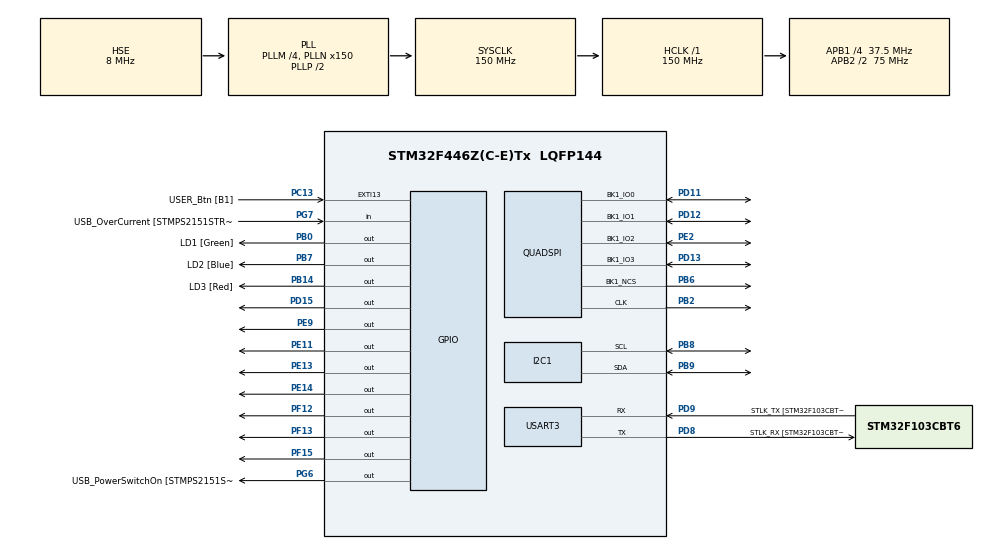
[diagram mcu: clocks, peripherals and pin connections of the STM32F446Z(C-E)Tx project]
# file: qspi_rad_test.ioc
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Mcu.Family=STM32F4
Mcu.Name=STM32F446Z(C-E)Tx
Mcu.Package=LQFP144
NVIC.PriorityGroup=NVIC_PRIORITYGROUP_4
PA10.GPIO_Label=USB_ID
PA10.Signal=USB_OTG_FS_ID
PA11.GPIO_Label=USB_DM
PA11.Signal=USB_OTG_FS_DM
PA12.GPIO_Label=USB_DP
PA12.Signal=USB_OTG_FS_DP
PA13.GPIO_Label=TMS
PA13.Mode=Serial_Wire
PA13.Signal=SYS_JTMS-SWDIO
PA14.GPIO_Label=TCK
PA14.Mode=Serial_Wire
PA14.Signal=SYS_JTCK-SWCLK
PA8.GPIO_Label=USB_SOF [TP1]
PA8.Signal=USB_OTG_FS_SOF
PA9.GPIO_Label=USB_VBUS
PA9.Signal=USB_OTG_FS_VBUS
PB0.GPIO_Label=LD1 [Green]
PB0.Signal=GPIO_Output
PB14.GPIO_Label=LD3 [Red]
PB14.Signal=GPIO_Output
PB2.Mode=Single Bank 1
PB2.Signal=QUADSPI_CLK
PB6.Mode=Single Bank 1
PB6.Signal=QUADSPI_BK1_NCS
PB7.GPIO_Label=LD2 [Blue]
PB7.Signal=GPIO_Output
PB8.Mode=I2C
PB8.Signal=I2C1_SCL
PB9.Mode=I2C
PB9.Signal=I2C1_SDA
PC13.GPIO_Label=USER_Btn [B1]
PC13.Signal=GPXTI13
PC14-OSC32_IN.Mode=LSE-External-Oscillator
PC14-OSC32_IN.Signal=RCC_OSC32_IN
PC15-OSC32_OUT.Mode=LSE-External-Oscillator
PC15-OSC32_OUT.Signal=RCC_OSC32_OUT
PD11.Mode=Single Bank 1
PD11.Signal=QUADSPI_BK1_IO0
PD12.Mode=Single Bank 1
PD12.Signal=QUADSPI_BK1_IO1
PD13.Mode=Single Bank 1
PD13.Signal=QUADSPI_BK1_IO3
PD15.Signal=GPIO_Output
PD8.GPIO_Label=STLK_RX [STM32F103CBT6_PA3]
PD8.Mode=Asynchronous
PD8.Signal=USART3_TX
PD9.GPIO_Label=STLK_TX [STM32F103CBT6_PA2]
PD9.Mode=Asynchronous
PD9.Signal=USART3_RX
PE11.Signal=GPIO_Output
PE13.Signal=GPIO_Output
PE14.Signal=GPIO_Output
PE2.Mode=Single Bank 1
PE2.Signal=QUADSPI_BK1_IO2
PE9.Signal=GPIO_Output
PF12.Signal=GPIO_Output
PF13.Signal=GPIO_Output
PF15.Signal=GPIO_Output
PG6.GPIO_Label=USB_PowerSwitchOn [STMPS2151STR_EN]
PG6.Signal=GPIO_Output
PG7.GPIO_Label=USB_OverCurrent [STMPS2151STR_FAULT]
PG7.Signal=GPIO_Input
PH0-OSC_IN.GPIO_Label=MCO [STM32F103CBT6_PA8]
PH0-OSC_IN.Mode=HSE-External-Clock-Source
PH0-OSC_IN.Signal=RCC_OSC_IN
PH1-OSC_OUT.Mode=HSE-External-Clock-Source
PH1-OSC_OUT.Signal=RCC_OSC_OUT
ProjectManager.HeapSize=0x200
ProjectManager.StackSize=0x400
ProjectManager.TargetToolchain=STM32CubeIDE
QUADSPI.ChipSelectHighTime=QSPI_CS_HIGH_TIME_4_CYCLE
QUADSPI.ClockPrescaler=2
QUADSPI.FifoThreshold=4
QUADSPI.FlashSize=24
QUADSPI.SampleShifting=QSPI_SAMPLE_SHIFTING_HALFCYCLE
RCC.48MHZClocksFreq_Value=24000000
RCC.AHBFreq_Value=150000000
RCC.APB1CLKDivider=RCC_HCLK_DIV4
RCC.APB1Freq_Value=37500000
RCC.APB1TimFreq_Value=75000000
RCC.APB2CLKDivider=RCC_HCLK_DIV2
RCC.APB2Freq_Value=75000000
RCC.APB2TimFreq_Value=150000000
RCC.CortexFreq_Value=150000000
RCC.HCLKFreq_Value=150000000
RCC.HSE_VALUE=8000000
RCC.HSI_VALUE=16000000
RCC.PLLM=4
RCC.PLLMUL=RCC_PLL_MUL9
RCC.PLLN=150
RCC.PLLQ=5
RCC.PLLSourceVirtual=RCC_PLLSOURCE_HSE
RCC.PRESCALERUSB=RCC_USBCLKSOURCE_PLL_DIV1_5
RCC.SYSCLKFreq_VALUE=150000000
RCC.SYSCLKSource=RCC_SYSCLKSOURCE_PLLCLK
RCC.SYSCLKSourceVirtual=RCC_SYSCLKSOURCE_PLLCLK
RCC.USBFreq_Value=60000000
RCC.VCOOutputFreq_Value=300000000
USART3.VirtualMode=VM_ASYNC
board=NUCLEO-F446ZE

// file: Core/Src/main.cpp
/* USER CODE BEGIN Header */
/**
  ******************************************************************************
  * @file           : main.c
  * @brief          : Main program body
  ******************************************************************************
  * @attention
  *
  * <h2><center>&copy; Copyright (c) 2022 STMicroelectronics.
  * All rights reserved.</center></h2>
  *
  * This software component is licensed by ST under BSD 3-Clause license,
  * the "License"; You may not use this file except in compliance with the
  * License. You may obtain a copy of the License at:
  *                        opensource.org/licenses/BSD-3-Clause
  *
  ******************************************************************************
  */
/* USER CODE END Header */
#include "main.h"
#include "i2c.h"
#include "quadspi.h"
#include "usart.h"
#include "gpio.h"

/* USER CODE BEGIN Includes */
#include "erpc_hal_uart_transport.hpp"
#include "erpc_mbf_setup.h"
#include "erpc_server_setup.h"
#include "erpc_setup_hal_uart.hpp"
#include "erpc_transport_setup.h"
#include "qspi_rad_test.h"
#include "qspi_rad_test_server.h"
/* USER CODE END Includes */

void SystemClock_Config(void);

int main(void)
{

  /* MCU Configuration--------------------------------------------------------*/

  /* Reset of all peripherals, Initializes the Flash interface and the Systick. */
  HAL_Init();

  /* Configure the system clock */
  SystemClock_Config();

  /* Initialize all configured peripherals */
  MX_GPIO_Init();
  MX_USART3_UART_Init();
  MX_QUADSPI_Init();
  MX_I2C1_Init();
  /* USER CODE BEGIN 2 */

	erpc_transport_t transport = erpc_transport_hal_uart_init(&huart3);
	erpc_mbf_t message_buffer_factory = erpc_mbf_static_init();
	erpc_server_init(transport, message_buffer_factory);
	erpc_add_service_to_server(create_QSPIService_service());

  /* USER CODE END 2 */

  /* Infinite loop */
  /* USER CODE BEGIN WHILE */
  while (1)
  {
	  erpc_server_poll();
    /* USER CODE END WHILE */

  }
}

void SystemClock_Config(void)
{
  RCC_OscInitTypeDef RCC_OscInitStruct = {0};
  RCC_ClkInitTypeDef RCC_ClkInitStruct = {0};

  /** Configure the main internal regulator output voltage
  */
  __HAL_RCC_PWR_CLK_ENABLE();
  __HAL_PWR_VOLTAGESCALING_CONFIG(PWR_REGULATOR_VOLTAGE_SCALE1);
  /** Initializes the RCC Oscillators according to the specified parameters
  * in the RCC_OscInitTypeDef structure.
  */
  RCC_OscInitStruct.OscillatorType = RCC_OSCILLATORTYPE_HSE;
  RCC_OscInitStruct.HSEState = RCC_HSE_BYPASS;
  RCC_OscInitStruct.PLL.PLLState = RCC_PLL_ON;
  RCC_OscInitStruct.PLL.PLLSource = RCC_PLLSOURCE_HSE;
  RCC_OscInitStruct.PLL.PLLM = 4;
  RCC_OscInitStruct.PLL.PLLN = 150;
  RCC_OscInitStruct.PLL.PLLP = RCC_PLLP_DIV2;
  RCC_OscInitStruct.PLL.PLLQ = 5;
  RCC_OscInitStruct.PLL.PLLR = 2;
  if (HAL_RCC_OscConfig(&RCC_OscInitStruct) != HAL_OK)
  {
    Error_Handler();
  }
  /** Initializes the CPU, AHB and APB buses clocks
  */
  RCC_ClkInitStruct.ClockType = RCC_CLOCKTYPE_HCLK|RCC_CLOCKTYPE_SYSCLK
                              |RCC_CLOCKTYPE_PCLK1|RCC_CLOCKTYPE_PCLK2;
  RCC_ClkInitStruct.SYSCLKSource = RCC_SYSCLKSOURCE_PLLCLK;
  RCC_ClkInitStruct.AHBCLKDivider = RCC_SYSCLK_DIV1;
  RCC_ClkInitStruct.APB1CLKDivider = RCC_HCLK_DIV4;
  RCC_ClkInitStruct.APB2CLKDivider = RCC_HCLK_DIV2;

  if (HAL_RCC_ClockConfig(&RCC_ClkInitStruct, FLASH_LATENCY_4) != HAL_OK)
  {
    Error_Handler();
  }
}

void Error_Handler(void)
{
  __disable_irq();
  while (1)
  {
  }
}

/************************ (C) COPYRIGHT STMicroelectronics *****END OF FILE****/
